# HC32M120 register map
File version: 1.0
CPU: CM0+ r0p1, little endian, no MPU, no FPU, 2 interrupt priority bits
Registers are 32-bit, read-write, reset 0x0 unless marked. A register's access mark holds for its fields unless they carry their own. Offsets are from the block's base; [hi:lo] are bit positions; {n}, {i} and the like mark numbered series.

## I2C
Base 0x40004800
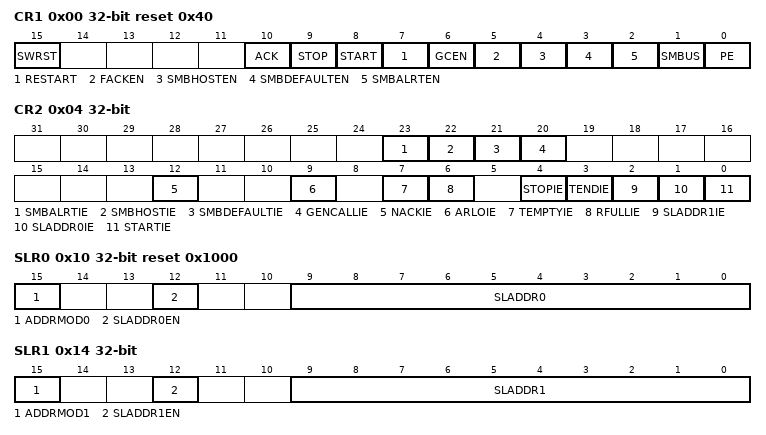
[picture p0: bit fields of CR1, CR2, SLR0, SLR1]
0x00 CR1 reset 0x40
  [15] SWRST, [10] ACK, [9] STOP, [8] START, [7] RESTART, [6] GCEN, [5] FACKEN, [4] SMBHOSTEN, [3] SMBDEFAULTEN, [2] SMBALRTEN, [1] SMBUS, [0] PE
0x04 CR2
  [23] SMBALRTIE, [22] SMBHOSTIE, [21] SMBDEFAULTIE, [20] GENCALLIE, [12] NACKIE, [9] ARLOIE, [7] TEMPTYIE, [6] RFULLIE, [4] STOPIE, [3] TENDIE, [2] SLADDR1IE, [1] SLADDR0IE, [0] STARTIE
0x0C CR4 reset 0x300307
  [10] BUSWAIT
0x10 SLR0 reset 0x1000
  [15] ADDRMOD0, [12] SLADDR0EN, [9:0] SLADDR0
0x14 SLR1
  [15] ADDRMOD1, [12] SLADDR1EN, [9:0] SLADDR1
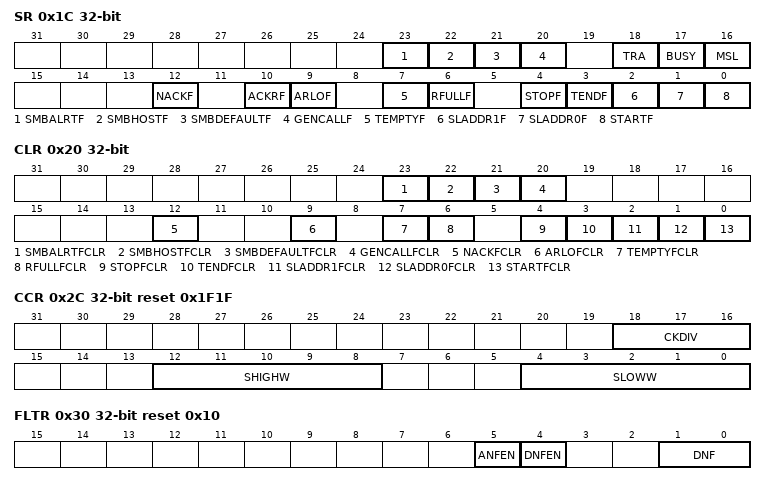
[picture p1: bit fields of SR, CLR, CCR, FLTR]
0x1C SR
  [23] SMBALRTF ro, [22] SMBHOSTF ro, [21] SMBDEFAULTF ro, [20] GENCALLF ro, [18] TRA, [17] BUSY ro, [16] MSL, [12] NACKF ro, [10] ACKRF ro, [9] ARLOF ro, [7] TEMPTYF ro, [6] RFULLF ro, [4] STOPF ro, [3] TENDF ro, [2] SLADDR1F ro, [1] SLADDR0F ro, [0] STARTF ro
0x20 CLR wo
  [23] SMBALRTFCLR, [22] SMBHOSTFCLR, [21] SMBDEFAULTFCLR, [20] GENCALLFCLR, [12] NACKFCLR, [9] ARLOFCLR, [7] TEMPTYFCLR, [6] RFULLFCLR, [4] STOPFCLR, [3] TENDFCLR, [2] SLADDR1FCLR, [1] SLADDR0FCLR, [0] STARTFCLR
0x24 DTR 8-bit reset 0xFF
  [7:0] DT
0x28 DRR 8-bit
  [7:0] DR
0x2C CCR reset 0x1F1F
  [18:16] CKDIV, [12:8] SHIGHW, [4:0] SLOWW
0x30 FLTR reset 0x10
  [5] ANFEN, [4] DNFEN, [1:0] DNF

## ICG
Base 0x000000C0
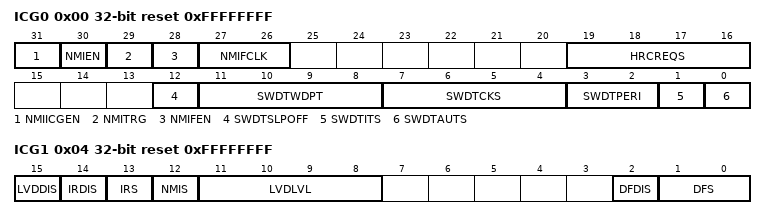
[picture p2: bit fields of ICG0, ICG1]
0x00 ICG0 ro reset 0xFFFFFFFF
  [31] NMIICGEN, [30] NMIEN, [29] NMITRG, [28] NMIFEN, [27:26] NMIFCLK, [19:16] HRCREQS, [12] SWDTSLPOFF, [11:8] SWDTWDPT, [7:4] SWDTCKS, [3:2] SWDTPERI, [1] SWDTITS, [0] SWDTAUTS
0x04 ICG1 ro reset 0xFFFFFFFF
  [15] LVDDIS, [14] IRDIS, [13] IRS, [12] NMIS, [11:8] LVDLVL, [2] DFDIS, [1:0] DFS
{0x0+4i} ICG{i} ro reset 0xFFFFFFFF (reset mask 0x0) (i=2..7)

## INTC
Base 0x40011000
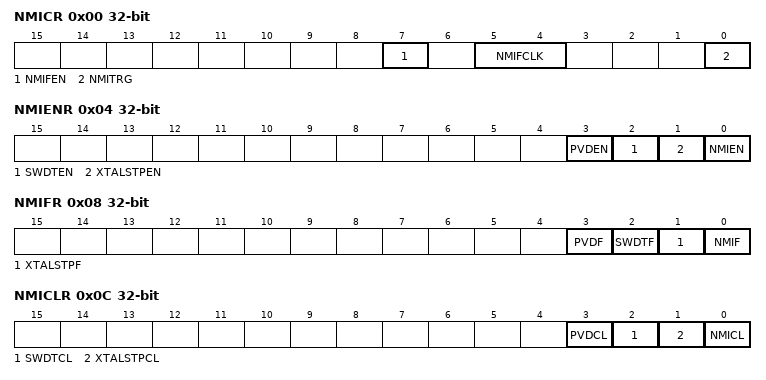
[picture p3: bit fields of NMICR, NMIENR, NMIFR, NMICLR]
0x00 NMICR
  [7] NMIFEN, [5:4] NMIFCLK, [0] NMITRG
0x04 NMIENR
  [3] PVDEN, [2] SWDTEN, [1] XTALSTPEN, [0] NMIEN
0x08 NMIFR ro
  [3] PVDF, [2] SWDTF, [1] XTALSTPF, [0] NMIF
0x0C NMICLR
  [3] PVDCL, [2] SWDTCL, [1] XTALSTPCL, [0] NMICL
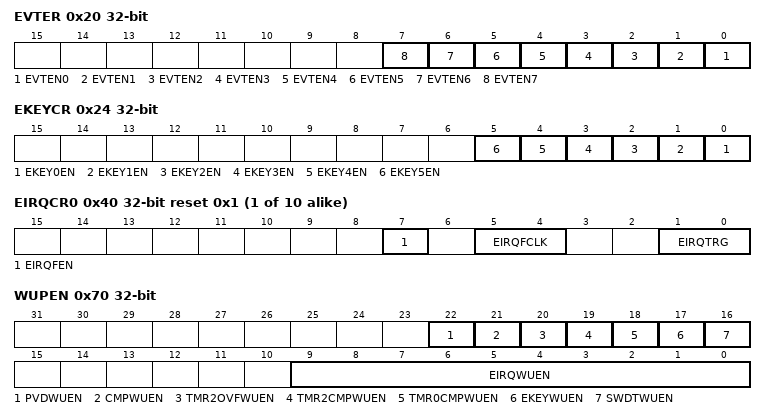
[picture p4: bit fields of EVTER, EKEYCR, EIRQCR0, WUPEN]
0x20 EVTER
  [n] EVTEN{n} (n=0..7)
0x24 EKEYCR
  [n] EKEY{n}EN (n=0..5)
0x3C FPRCR
  [7:0] FPRC
{0x40+4i} EIRQCR{i} reset 0x1 (i=0..9)
  [7] EIRQFEN, [5:4] EIRQFCLK, [1:0] EIRQTRG
0x70 WUPEN (reset mask 0x1C703FF)
  [22] PVDWUEN, [21] CMPWUEN, [20] TMR2OVFWUEN, [19] TMR2CMPWUEN, [18] TMR0CMPWUEN, [17] EKEYWUEN, [16] SWDTWUEN, [9:0] EIRQWUEN
0x74 EIRQFR
  [9:0] EIRQF
0x78 EIRQCLR
  [9:0] EIRQCL
{0x80+4i} ISELAR{i} (i=8..23)
  [3:0] ISEL
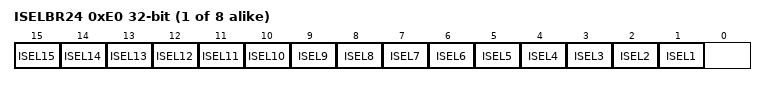
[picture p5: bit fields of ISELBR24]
{0x80+4i} ISELBR{i} (i=24..31)
  [n] ISEL{n} (n=1..15)

## PWC
Base 0x40014000
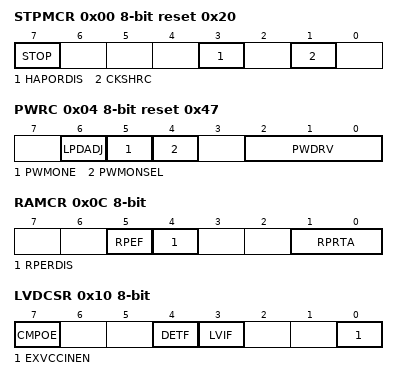
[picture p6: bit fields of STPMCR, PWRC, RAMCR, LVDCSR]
0x00 STPMCR 8-bit reset 0x20
  [7] STOP, [3] HAPORDIS, [1] CKSHRC
0x04 PWRC 8-bit reset 0x47
  [6] LPDADJ, [5] PWMONE, [4] PWMONSEL, [2:0] PWDRV
0x0C RAMCR 8-bit
  [5] RPEF, [4] RPERDIS, [1:0] RPRTA
0x10 LVDCSR 8-bit
  [7] CMPOE, [4] DETF, [3] LVIF ro, [0] EXVCCINEN
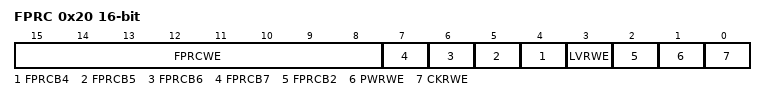
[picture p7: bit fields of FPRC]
0x20 FPRC 16-bit
  [15:8] FPRCWE wo, [n] FPRCB{n} (n=4..7), [3] LVRWE, [2] FPRCB2, [1] PWRWE, [0] CKRWE
0x40 DBGC 8-bit
  [0] DBGEN

## RMU
Base 0x40014100
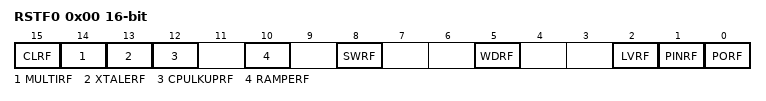
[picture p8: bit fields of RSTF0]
0x00 RSTF0 16-bit
  [15] CLRF, [14] MULTIRF, [13] XTALERF, [12] CPULKUPRF, [10] RAMPERF, [8] SWRF, [5] WDRF, [2] LVRF, [1] PINRF, [0] PORF

## SPI
Base 0x40003800
0x00 DR
  [15:0] SPD
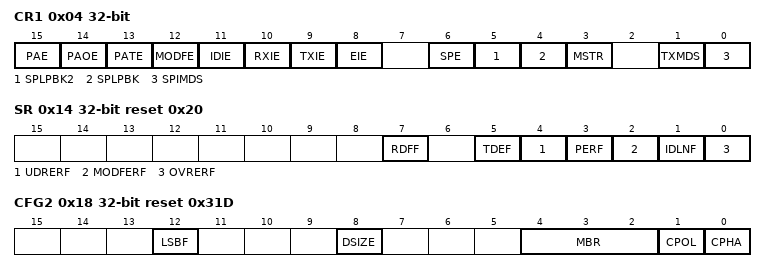
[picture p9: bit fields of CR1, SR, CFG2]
0x04 CR1
  [15] PAE, [14] PAOE, [13] PATE, [12] MODFE, [11] IDIE, [10] RXIE, [9] TXIE, [8] EIE, [6] SPE, [5] SPLPBK2, [4] SPLPBK, [3] MSTR, [1] TXMDS, [0] SPIMDS
0x0C CFG1 reset 0x10
  [8] SS0PV
0x14 SR reset 0x20
  [7] RDFF, [5] TDEF, [4] UDRERF, [3] PERF, [2] MODFERF, [1] IDLNF ro, [0] OVRERF
0x18 CFG2 reset 0x31D
  [12] LSBF, [8] DSIZE, [4:2] MBR, [1] CPOL, [0] CPHA

## SWDT
Base 0x4000CC00
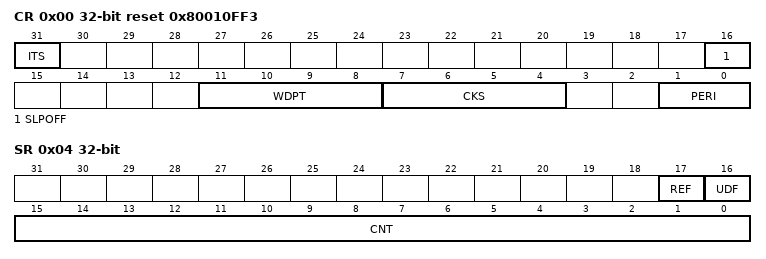
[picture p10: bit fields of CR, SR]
0x00 CR reset 0x80010FF3
  [31] ITS, [16] SLPOFF, [11:8] WDPT, [7:4] CKS, [1:0] PERI
0x04 SR
  [17] REF, [16] UDF, [15:0] CNT ro
0x08 RR
  [15:0] RF
